# AVR32SD32 register map
Vendor: Atmel; File version: 1.0
CPU: other r0p0, little endian, no MPU, no FPU, 4 interrupt priority bits
Registers are 8-bit, read-write, reset 0x0 unless marked. A register's access mark holds for its fields unless they carry their own. Offsets are from the block's base; [hi:lo] are bit positions; {n}, {i} and the like mark numbered series; 'fields as' and 'values as' point back to an identical list.

## GPR — General Purpose Registers
Base 0x0080001C
{0x0+i} GPR{i} (i=0..3) — General Purpose Register {i}

## LOCK — Lockbits
Base 0x00801040
0x00 KEY 32-bit (reset mask 0xFF) — Lock Key Bits
  [31:0] KEY — Lock Key
    0=RWLOCK; 0x5CC5C55C=NOLOCK (No locks)

## MVIO — Multi-Voltage I/O
Base 0x00800100
0x00 INTCTRL — Interrupt Control
  [0] VDDIO2IE — VDDIO2 Interrupt Enable
0x01 INTFLAGS — Interrupt Flags
  [0] VDDIO2IF — VDDIO2 Interrupt Flag
0x02 STATUS ro
  [0] VDDIO2S — VDDIO2 Status

## NVMCTRL — Non-volatile Memory Controller
Base 0x00801000
0x00 CTRLA — Control A
  [6:0] CMD — Command
    0=NOCMD (No Command); 1=NOOP (No Operation); 2=FLWR (Flash Write); 8=FLPER (Flash Page Erase); 9=FLMPER2 (Flash Multi-Page Erase 2 pages); 10=FLMPER4 (Flash Multi-Page Erase 4 pages); 11=FLMPER8 (Flash Multi-Page Erase 8 pages); 12=FLMPER16 (Flash Multi-Page Erase 16 pages); 13=FLMPER32 (Flash Multi-Page Erase 32 pages); 18=EEWR (EEPROM Write); 19=EEERWR (EEPROM Erase and Write); 24=EEBER (EEPROM Byte Erase); 25=EEMBER2 (EEPROM Multi-Byte Erase 2 bytes); 26=EEMBER4 (EEPROM Multi-Byte Erase 4 bytes); 27=EEMBER8 (EEPROM Multi-Byte Erase 8 bytes); 28=EEMBER16 (EEPROM Multi-Byte Erase 16 bytes); 29=EEMBER32 (EEPROM Multi-Byte Erase 32 bytes); 32=CHER (Chip Erase Command); 48=EECHER (EEPROM Erase Command)
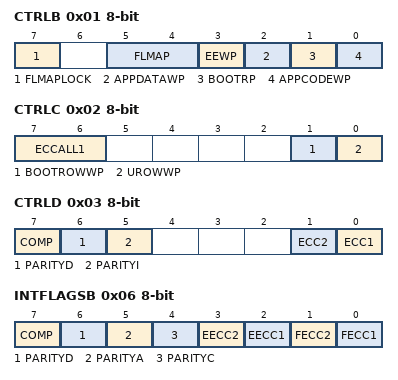
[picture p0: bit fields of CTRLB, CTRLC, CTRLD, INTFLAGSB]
0x01 CTRLB — Control B
  [7] FLMAPLOCK — Flash Mapping Lock
  [5:4] FLMAP — Flash Mapping in Data space
    {v}=SECTION{v} (Flash section {v}) (v=0..3)
  [3] EEWP — EEPROM Write Protect
  [2] APPDATAWP — Application Data Write Protect
  [1] BOOTRP — Boot Read Protect
  [0] APPCODEWP — Application Code Write Protect
0x02 CTRLC — Control C
  [7:6] ECCALL1 — Erased Flash ECC check
    0=CHECKALL (ECC check on all flash words including those read as all-ones.); 1=DISALL (Disregard ECC check on flash words read as all-ones from the entire flash.); 2=DISAPPDATA (Disregard ECC check on flash words read as all-ones from from the APPDATA section or USER row); 3=DISAPPDATAEE (Disregard ECC check on EEPROM bytes read as all-ones, and flash words read as all-ones from the APPDATA section, USER row, or BOOTROW)
  [1] BOOTROWWP — Boot Row Write Protect
  [0] UROWWP — User Row Write Protect
0x03 CTRLD — Control D
  [7] COMP — ECC comparator error inject
  [6] PARITYD — Parity error inject on Data Read
  [5] PARITYI — Parity error inject on Instruction Fetch
  [1] ECC2 — 2-bit ECC error inject
  [0] ECC1 — 1-bit ECC error inject
0x04 INTCTRLA — Interrupt Control A
  [0] EEREADY — EEPROM Ready
0x05 INTFLAGSA — Interrupt Flags A
  [0] EEREADY — EEPROM Ready
0x06 INTFLAGSB — Interrupt Flags B
  [7] COMP — Comparator error detected
  [6] PARITYD — Parity error on Write Data detected
  [5] PARITYA — Parity error on Address detected
  [4] PARITYC — Parity error on Control signals detected
  [3] EECC2 — EEPROM multibit error detected
  [2] EECC1 — EEPROM 1-bit error detected
  [1] FECC2 — Flash multibit error detected
  [0] FECC1 — Flash 1-bit ECC error detected
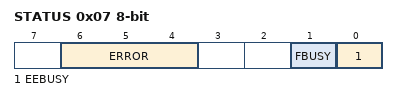
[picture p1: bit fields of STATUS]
0x07 STATUS
  [6:4] ERROR — Write error
    0=NONE (No Error); 1=INVALIDCMD (Write command not selected or not valid); 2=WRITEPROTECT (Write to section not allowed); 3=CMDCOLLISION (Selecting new write command while programming is ongoing)
  [1] FBUSY ro — Flash busy
  [0] EEBUSY ro — EEPROM busy
0x08 DATA 32-bit ro (reset mask 0xFF)
0x0C ADDR 32-bit (reset mask 0xFF) — Address
  [23:0] ADDR
0x10 PARITY ro — ECC Parity
0x11 SYNDROME ro — ECC Syndrome

## PORTA — I/O Ports
Base 0x00800400
Same registers: PORTD 0x00800460, PORTF 0x008004A0
0x00 DIR — Data Direction
0x01 DIRSET — Data Direction Set
0x02 DIRCLR — Data Direction Clear
0x03 DIRTGL — Data Direction Toggle
0x04 OUT — Output Value
0x05 OUTSET — Output Value Set
0x06 OUTCLR — Output Value Clear
0x07 OUTTGL — Output Value Toggle
0x08 IN — Input Value
0x09 INTFLAGS — Interrupt Flags
  [7:0] INT — Pin Interrupt Flag
0x0A PORTCTRL — Port Control
  [0] SRL — Slew Rate Limit Enable
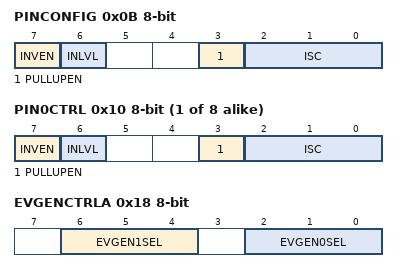
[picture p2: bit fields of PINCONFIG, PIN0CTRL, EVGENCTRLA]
0x0B PINCONFIG — Pin Control Config
  [7] INVEN — Inverted I/O Enable
  [6] INLVL — Input Level Select
    0=ST (Schmitt-Trigger input level); 1=TTL (TTL Input level)
  [3] PULLUPEN — Pullup enable
  [2:0] ISC — Input/Sense Configuration
    0=INTDISABLE (Interrupt disabled but input buffer enabled); 1=BOTHEDGES (Sense Both Edges); 2=RISING (Sense Rising Edge); 3=FALLING (Sense Falling Edge); 4=INPUT_DISABLE (Digital Input Buffer disabled); 5=LEVEL (Sense low Level)
0x0C PINCTRLUPD — Pin Control Update
0x0D PINCTRLSET — Pin Control Set
0x0E PINCTRLCLR — Pin Control Clear
{0x10+i} PIN{i}CTRL (i=0..7) — Pin {i} Control
  fields as PINCONFIG
0x18 EVGENCTRLA — Event Generation Control A
  [6:4] EVGEN1SEL — Event Generator 1 Select
    {v}=PIN{v} (Pin {v} used as event generator) (v=0..7)
  [2:0] EVGEN0SEL — Event Generator 0 Select
    {v}=PIN{v} (Pin {v} used as event generator) (v=0..7)

## PORTC — I/O Ports
Base 0x00800440
Registers as PORTA, without PORTCTRL; these are added or differ:
0x0A PORTCTRL — Port Control
  [0] SRL — Slew Rate Limit Enable
